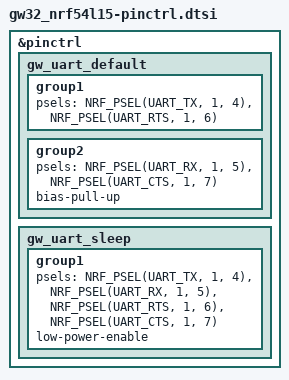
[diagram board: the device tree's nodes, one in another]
#include <zephyr/dt-bindings/pinctrl/nrf-pinctrl.h>

&pinctrl {
	gw_uart_default: gw_uart_default {
		group1 {
			psels = <NRF_PSEL(UART_TX, 1, 4)>, <NRF_PSEL(UART_RTS, 1, 6)>;
		};
		group2 {
			psels = <NRF_PSEL(UART_RX, 1, 5)>, <NRF_PSEL(UART_CTS, 1, 7)>;
			bias-pull-up;
		};
	};
	gw_uart_sleep: gw_uart_sleep {
		group1 {
			psels = <NRF_PSEL(UART_TX, 1, 4)>, <NRF_PSEL(UART_RX, 1, 5)>,
				<NRF_PSEL(UART_RTS, 1, 6)>, <NRF_PSEL(UART_CTS, 1, 7)>;
			low-power-enable;
		};
	};
};
